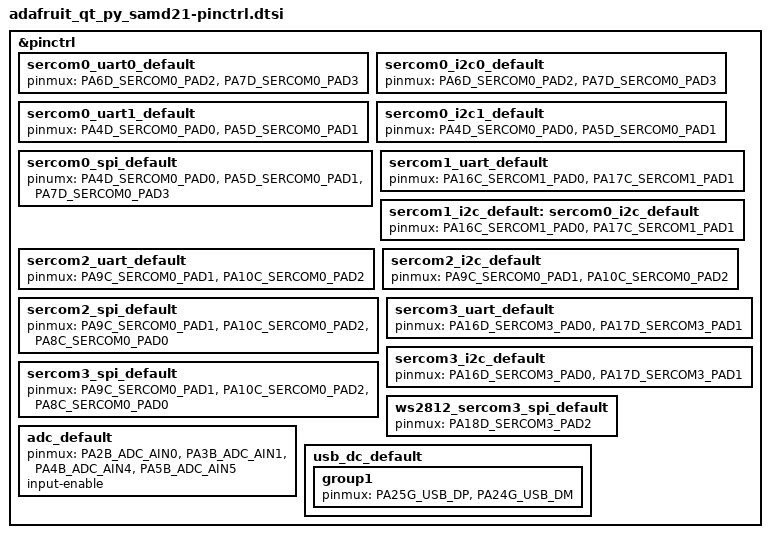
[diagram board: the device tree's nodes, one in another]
/*
 * Copyright (c) 2026, The Zephyr Project Contributors
 * SPDX-License-Identifier: Apache-2.0
 */

#include <dt-bindings/pinctrl/samd21-da1eXabcd-pinctrl.h>

&pinctrl {
	sercom0_uart0_default: sercom0_uart0_default {
		pinmux = <PA6D_SERCOM0_PAD2>,
			 <PA7D_SERCOM0_PAD3>;
	};

	sercom0_i2c0_default: sercom0_i2c0_default {
		pinmux = <PA6D_SERCOM0_PAD2>,
			 <PA7D_SERCOM0_PAD3>;
	};

	sercom0_uart1_default: sercom0_uart1_default {
		pinmux = <PA4D_SERCOM0_PAD0>,
			 <PA5D_SERCOM0_PAD1>;
	};

	sercom0_i2c1_default: sercom0_i2c1_default {
		pinmux = <PA4D_SERCOM0_PAD0>,
			 <PA5D_SERCOM0_PAD1>;
	};

	sercom0_spi_default: sercom0_spi_default {
		pinumx = <PA4D_SERCOM0_PAD0>,
			 <PA5D_SERCOM0_PAD1>,
			 <PA7D_SERCOM0_PAD3>;
	};

	sercom1_uart_default: sercom1_uart_default {
		pinmux = <PA16C_SERCOM1_PAD0>,
			 <PA17C_SERCOM1_PAD1>;
	};

	sercom1_i2c_default: sercom0_i2c_default {
		pinmux = <PA16C_SERCOM1_PAD0>,
			 <PA17C_SERCOM1_PAD1>;
	};

	sercom2_uart_default: sercom2_uart_default {
		pinmux = <PA9C_SERCOM0_PAD1>,
			 <PA10C_SERCOM0_PAD2>;
	};

	sercom2_i2c_default: sercom2_i2c_default {
		pinmux = <PA9C_SERCOM0_PAD1>,
			 <PA10C_SERCOM0_PAD2>;
	};

	sercom2_spi_default: sercom2_spi_default {
		pinmux = <PA9C_SERCOM0_PAD1>,
			 <PA10C_SERCOM0_PAD2>,
			 <PA8C_SERCOM0_PAD0>;
	};

	sercom3_uart_default: sercom3_uart_default {
		pinmux = <PA16D_SERCOM3_PAD0>,
			 <PA17D_SERCOM3_PAD1>;
	};

	sercom3_i2c_default: sercom3_i2c_default {
		pinmux = <PA16D_SERCOM3_PAD0>,
			 <PA17D_SERCOM3_PAD1>;
	};

	sercom3_spi_default: sercom3_spi_default {
		pinmux = <PA9C_SERCOM0_PAD1>,
			 <PA10C_SERCOM0_PAD2>,
			 <PA8C_SERCOM0_PAD0>;
	};

	ws2812_sercom3_spi_default: ws2812_sercom3_spi_default {
		pinmux = <PA18D_SERCOM3_PAD2>;
	};

	adc_default: adc_default {
		pinmux =  <PA2B_ADC_AIN0>,
			  <PA3B_ADC_AIN1>,
			  <PA4B_ADC_AIN4>,
			  <PA5B_ADC_AIN5>;
		input-enable;
	};

	usb_dc_default: usb_dc_default {
		group1 {
			pinmux = <PA25G_USB_DP>,
				 <PA24G_USB_DM>;
		};
	};
};
